# RA4M1 register map
Vendor: Renesas Electronics Corporation; Series: RA4; File version: 1.2
CPU: CM4 r0p1, little endian, MPU, FPU, VTOR, 4 interrupt priority bits
Registers are 8-bit, read-write, reset 0x0 unless marked. A register's access mark holds for its fields unless they carry their own. Offsets are from the block's base; [hi:lo] are bit positions; {n}, {i} and the like mark numbered series; <NAME> marks a mode.

## SLCDC — Segment LCD Controller/Driver
Base 0x40082000
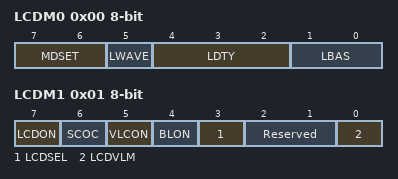
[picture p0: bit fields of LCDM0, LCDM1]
0x00 LCDM0 — LCD Mode Register 0
  [7:6] MDSET — LCD drive voltage generator selection
    0=External resistance division method; 1=Internal voltage boosting method; 2=Capacitor split method; 3=Setting prohibited
  [5] LWAVE — LCD display waveform selection
    0=Waveform A; 1=Waveform B
  [4:2] LDTY — Time Slice of LCD Display Select
    0=Static; 1=2-time slice; 2=3-time slice; 3=4-time slice; 5=8-time slice; other=others (Setting prohibited)
  [1:0] LBAS — LCD Display Bias Method Select
    0=1/2 bias method; 1=1/3 bias method; 2=1/4 bias method; 3=Setting prohibited
0x01 LCDM1 — LCD Mode Register 1
  [7] LCDON — LCD Display Enable/Disable
    0=Output ground level to segment/common pin(SCOC=0)/Display off (all segment outputs are deselected)(SCOC=1); 1=Output ground level to segment/common pin(SCOC=0)/Display on(SCOC=1)
  [6] SCOC — LCD Display Enable/Disable
    0=Output ground level to segment/common pin(LCDON=0)/Output ground level to segment/common pin(LCDON=1); 1=Display off (all segment outputs are deselected)(LCDON=0)/Display on(LCDON=1)
  [5] VLCON — Voltage boost circuit or capacitor split circuit operation enable/disable
    0=Stops voltage boost circuit or capacitor split circuit operation; 1=Enables voltage boost circuit or capacitor split circuit operation
  [4] BLON — Display data area control
    0=Displaying an A-pattern area data (lower four bits of LCD display data register)(LCDSEL=0)/Displaying a B-pattern area data (higher four bits of LCD display data register)(LCDSEL=1); 1=Alternately displaying A-pattern and B-pattern area data (blinking display corresponding to the constant-period interrupt (INTRTC) timing of the real-time clock (RTC))
  [3] LCDSEL — Display data area control
    0=Displaying an A-pattern area data (lower four bits of LCD display data register)(BLON=0)/Alternately displaying A-pattern and B-pattern area data (blinking display corresponding to the constant-period interrupt (INTRTC) timing of the real-time clock (RTC))(BLON=1); 1=Displaying a B-pattern area data (higher four bits of LCD display data register)(BLON=0)/Alternately displaying A-pattern and B-pattern area data (blinking display corresponding to the constant-period interrupt (INTRTC) timing of the real-time clock (RTC))(BLON=1)
  [2:1] Reserved — These bits are read as 00. The write value should be 00.
  [0] LCDVLM — Voltage Boosting Pin Initial Value Switching Control
    0=Set when VDD >= 2.7 V; 1=Set when VDD <= 4.2 V
0x02 LCDC0 — LCD Clock Control Register 0
  [5:0] LCDC — LCD clock (LCDCL)
    {v}=(Sub clock)/{v+21} or (LOCO clock)/{v+21} (v=1..8); 9=(Sub clock)/210 or (LOCO clock)/210; 17=(Main clock)/28 or (HOCO clock)/28; 18=(Main clock)/29 or (HOCO clock)/29; {v}=(Main clock)/{v+191} or (HOCO clock)/{v+191} (v=19..27); 43=(Main clock)/219 or (HOCO clock)/219; other=others (Other than above Setting prohibited)
0x03 VLCD reset 0x4 — LCD Boost Level Control Register
  [4:0] VLCD — Reference Voltage(Contrast Adjustment) Select
    4=Reference voltageselection(contrast adjustment): 1.00 V (default) VL4 voltage: 3.00 V(1/3 bias method)/4.00 V(1/4 bias method); 5=Reference voltageselection(contrast adjustment): 1.05 V VL4 voltage: 3.15 V(1/3 bias method)/4.20 V(1/4 bias method); 6=Reference voltageselection(contrast adjustment): 1.10 V VL4 voltage: 3.30 V(1/3 bias method)/4.40 V(1/4 bias method); 7=Reference voltageselection(contrast adjustment): 1.15 V VL4 voltage: 3.45 V(1/3 bias method)/4.60 V(1/4 bias method); 8=Reference voltageselection(contrast adjustment): 1.20 V VL4 voltage: 3.60 V(1/3 bias method)/4.80 V(1/4 bias method); 9=Reference voltageselection(contrast adjustment): 1.25 V VL4 voltage: 3.75 V(1/3 bias method)/5.00 V(1/4 bias method); 10=Reference voltageselection(contrast adjustment): 1.30 V VL4 voltage: 3.90 V(1/3 bias method)/5.20 V(1/4 bias method); 11=Reference voltageselection(contrast adjustment): 1.35 V VL4 voltage: 4.05 V(1/3 bias method)/Setting prohibited(1/4 bias method); 12=Reference voltageselection(contrast adjustment): 1.40 V VL4 voltage: 4.20 V(1/3 bias method)/Setting prohibited(1/4 bias method); 13=Reference voltageselection(contrast adjustment): 1.45 V VL4 voltage: 4.35 V(1/3 bias method)/Setting prohibited(1/4 bias method); 14=Reference voltageselection(contrast adjustment): 1.50 V VL4 voltage: 4.50 V(1/3 bias method)/Setting prohibited(1/4 bias method); 15=Reference voltageselection(contrast adjustment): 1.55 V VL4 voltage: 4.65 V(1/3 bias method)/Setting prohibited(1/4 bias method); 16=Reference voltageselection(contrast adjustment): 1.60 V VL4 voltage: 4.80 V(1/3 bias method)/Setting prohibited(1/4 bias method); 17=Reference voltageselection(contrast adjustment): 1.65 V VL4 voltage: 4.95 V(1/3 bias method)/Setting prohibited(1/4 bias method); 18=Reference voltageselection(contrast adjustment): 1.70 V VL4 voltage: 5.10 V(1/3 bias method)/Setting prohibited(1/4 bias method); 19=Reference voltageselection(contrast adjustment): 1.75 V VL4 voltage: 5.25 V(1/3 bias method)/Setting prohibited(1/4 bias method); other=others (Setting prohibited)
{0x100+i} SEG{i} (i=0..37) — LCD Display Data Register {i}
  [7:0] SEG — LCD Display Data
